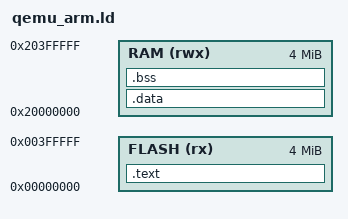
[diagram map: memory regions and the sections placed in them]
/* Linker script for ARM Cortex-M4 QEMU MPS2-AN385 board */
MEMORY
{
  FLASH (rx)  : ORIGIN = 0x00000000, LENGTH = 4M
  RAM   (rwx) : ORIGIN = 0x20000000, LENGTH = 4M
}

_estack = ORIGIN(RAM) + LENGTH(RAM);

SECTIONS
{
    .text :
    {
        KEEP(*(.isr_vector))
        *(.text*)
        *(.init)
        *(.fini)
        *(.ARM.extab*)
        __exidx_start = .;
        *(.ARM.exidx*)
        __exidx_end = .;

        . = ALIGN(4);
        PROVIDE_HIDDEN (__init_array_start = .);
        KEEP (*(SORT(.init_array.*)))
        KEEP (*(.init_array*))
        PROVIDE_HIDDEN (__init_array_end = .);

        . = ALIGN(4);
        PROVIDE_HIDDEN (__fini_array_start = .);
        KEEP (*(SORT(.fini_array.*)))
        KEEP (*(.fini_array*))
        PROVIDE_HIDDEN (__fini_array_end = .);

        . = ALIGN(8);
        *(.rodata)
        *(.rodata.*)
        *(.gnu.linkonce.r.*)
        . = ALIGN(8);
        _etext = .;
    } > FLASH

    .data : AT (_etext)
    {
        . = ALIGN(8);
        _sdata = .;
        *(.data._impure_data)
        *(.data)
        *(.data.*)
        *(.gnu.linkonce.d.*)
        . = ALIGN(8);
        _edata = .;
    } > RAM

    _sidata = LOADADDR(.data);

    .bss :
    {
        . = ALIGN(8);
        _sbss = .;
        __bss_start__ = .;
        *(.bss)
        *(.bss.*)
        *(COMMON)
        . = ALIGN(8);
        _ebss = .;
        __bss_end__ = .;
        end = .;
        __end__ = .;
    } > RAM
}
